VERSION "stellar_test_1.0"

NS_ :

BS_:

BU_: ECU1 ECU2 Gateway

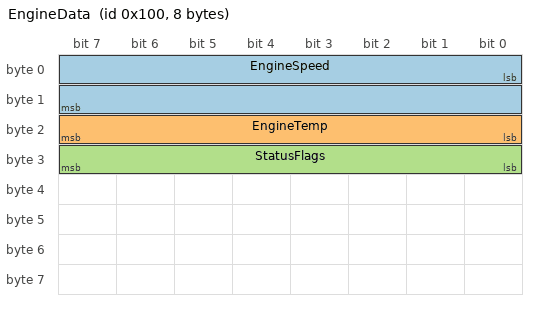
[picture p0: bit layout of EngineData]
BO_ 256 EngineData: 8 ECU1
 SG_ EngineSpeed : 0|16@1+ (0.25,0) [0|8000] "rpm" Gateway
 SG_ EngineTemp : 16|8@1- (1,-40) [-40|215] "degC" Gateway
 SG_ StatusFlags : 24|8@1+ (1,0) [0|255] "" Gateway

BO_ 2147483904 ChassisStatus: 8 ECU2
 SG_ WheelSpeedFL : 0|16@1+ (0.01,0) [0|655.35] "km/h" Gateway
 SG_ WheelSpeedFR : 16|16@1+ (0.01,0) [0|655.35] "km/h" Gateway

BO_ 512 IntelSignals: 8 ECU1
 SG_ IntelU12 : 3|12@1+ (1,0) [0|4095] "" Gateway
 SG_ IntelS12 : 20|12@1- (1,0) [-2048|2047] "" Gateway

BO_ 768 MotorolaSignals: 8 ECU1
 SG_ MotoU16 : 7|16@0+ (1,0) [0|65535] "" Gateway
 SG_ MotoS8 : 23|8@0- (1,0) [-128|127] "" Gateway

BO_ 1024 FactorOffset: 4 ECU1
 SG_ Scaled : 0|16@1+ (0.1,-50) [-50|6000] "unit" Gateway

BO_ 1280 SwitchStates: 1 ECU1
 SG_ Switch : 0|8@1+ (1,0) [0|2] "" Gateway

VAL_ 1280 Switch 0 "OFF" 1 "ON" 2 "ERROR" ;

BO_ 1536 MuxMessage: 2 ECU1
 SG_ Mode M : 0|8@1+ (1,0) [0|1] "" Gateway
 SG_ Speed m0 : 8|8@1+ (1,0) [0|255] "km/h" Gateway
 SG_ Temperature m1 : 8|8@1- (1,0) [-128|127] "degC" Gateway

BO_ 1792 CanFdSensors: 16 ECU1
 SG_ SensorA : 0|16@1+ (1,0) [0|65535] "" Gateway
 SG_ SensorB : 64|16@1+ (0.5,0) [0|32767.5] "V" Gateway

CM_ BO_ 256 "Engine data message";
CM_ SG_ 256 EngineSpeed "Engine speed";
